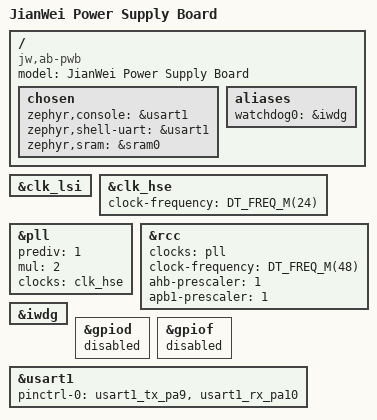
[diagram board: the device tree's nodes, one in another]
/dts-v1/;
#include <st/f0/stm32f051X8.dtsi>
#include <st/f0/stm32f051k8tx-pinctrl.dtsi>

/ {
	model = "JianWei Power Supply Board";
	compatible = "jw,ab-pwb";

	chosen {
		zephyr,console = &usart1;
		zephyr,shell-uart = &usart1;
		zephyr,sram = &sram0;
	};

	aliases {
		watchdog0 = &iwdg;
	};
};

/* clocks */
/* Note: max sysclk allowed is 48MHz */

&clk_lsi {
	status = "okay";
};

&clk_hse {
	clock-frequency = <DT_FREQ_M(24)>;
	status = "okay";
};

&pll {
	prediv = <1>;
	mul = <2>;
	clocks = <&clk_hse>;
	status = "okay";
};

&rcc {
	clocks = <&pll>;
	clock-frequency = <DT_FREQ_M(48)>;
	ahb-prescaler = <1>;
	apb1-prescaler = <1>;
};

&iwdg {
	status = "okay";
};

/* peripherals */

/* Due to limited available memory, don't enable gpiod and gpiof */
&gpiod {status = "disabled";};
&gpiof {status = "disabled";};

&usart1 {
	pinctrl-0 = <&usart1_tx_pa9 &usart1_rx_pa10>;
	pinctrl-names = "default";
	status = "okay";
};
